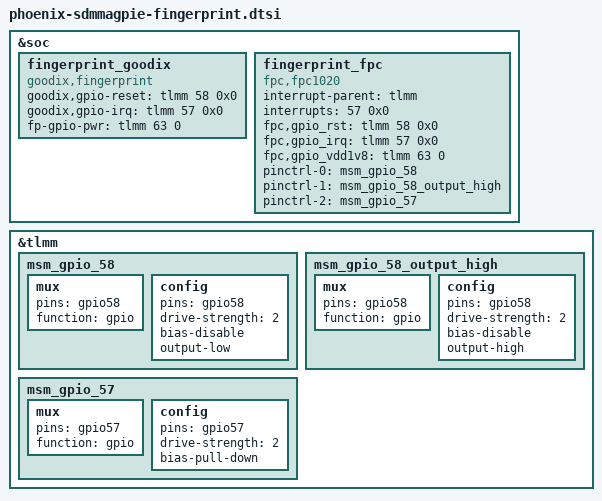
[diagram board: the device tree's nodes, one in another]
/*
 * Copyright (C) 2020 The LineageOS Project
 *
 * this file is for attribution only of phoenix
 * And public attribution of Xiaomi platforms (like G7B and so)
 */

&soc {
    fingerprint_goodix {
        compatible = "goodix,fingerprint";
        goodix,gpio-reset = <&tlmm 58 0x0>;
        goodix,gpio-irq = <&tlmm 57 0x0>;
        fp-gpio-pwr = <&tlmm 63 0>;
        status = "ok";
    };
    fingerprint_fpc {
        status = "ok";
        compatible = "fpc,fpc1020";
        interrupt-parent = <&tlmm>;
        interrupts = <57 0x0>;
        fpc,gpio_rst    = <&tlmm 58 0x0>;
        fpc,gpio_irq    = <&tlmm 57 0x0>;
        fpc,gpio_vdd1v8 = <&tlmm 63 0>;
        pinctrl-names = "fpc1020_reset_reset",
               "fpc1020_reset_active",
               "fpc1020_irq_active";

        pinctrl-0 = <&msm_gpio_58>;
        pinctrl-1 = <&msm_gpio_58_output_high>;
        pinctrl-2 = <&msm_gpio_57>;
    };
};

&tlmm {
    /* GPIO_58 : FP_RESET_N */
    msm_gpio_58: msm_gpio_58 {
        mux {
             pins = "gpio58";
             function = "gpio";
        };

        config {
            pins = "gpio58";
            drive-strength = <2>;
            bias-disable;
            output-low;
        };
    };

    /* GPIO_58 : FP_RESET_N, state device active*/
    msm_gpio_58_output_high: msm_gpio_58_output_high {
        mux {
            pins = "gpio58";
            function = "gpio";
        };

        config {
            pins = "gpio58";
            drive-strength = <2>;
            bias-disable;
            output-high;
        };
    };

    /* GPIO_57 : FP_INT_N */
    msm_gpio_57: msm_gpio_57 {
        mux {
            pins = "gpio57";
            function = "gpio";
        };

        config {
            pins = "gpio57";
            drive-strength = <2>;
            bias-pull-down;
        };
    };
};
